AUTOSAR XML (schema 4-0-3)
package /ComponentTypes
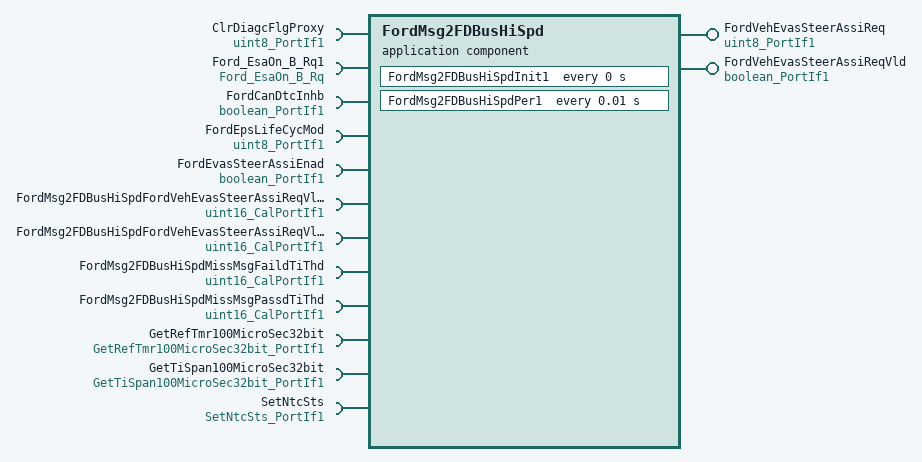
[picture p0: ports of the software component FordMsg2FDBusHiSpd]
  application sw component type FordMsg2FDBusHiSpd
    provide port FordVehEvasSteerAssiReq: nonqueued-sender-com-spec{data-element=Val, init-value=1}, provided-interface=uint8_PortIf1
    provide port FordVehEvasSteerAssiReqVld: nonqueued-sender-com-spec{data-element=Logl, init-value=0}, provided-interface=boolean_PortIf1
    12 x require port:
      ClrDiagcFlgProxy: nonqueued-receiver-com-spec{data-element=Val, filter=data-filter-type=ALWAYS, init-value=0}, required-interface=uint8_PortIf1
      Ford_EsaOn_B_Rq1: nonqueued-receiver-com-spec{data-element=Ford_EsaOn_B_Rq, filter=data-filter-type=ALWAYS, init-value=1}, required-interface=Ford_EsaOn_B_Rq
      FordCanDtcInhb: nonqueued-receiver-com-spec{data-element=Logl, filter=data-filter-type=ALWAYS, init-value=1}, required-interface=boolean_PortIf1
      FordEpsLifeCycMod: nonqueued-receiver-com-spec{data-element=Val, filter=data-filter-type=ALWAYS, init-value=0}, required-interface=uint8_PortIf1
      FordEvasSteerAssiEnad: nonqueued-receiver-com-spec{data-element=Logl, filter=data-filter-type=ALWAYS, init-value=0}, required-interface=boolean_PortIf1
      FordMsg2FDBusHiSpdFordVehEvasSteerAssiReqVldNotRxdTiThd: parameter-require-com-spec{init-value=5000, parameter=Val}, required-interface=uint16_CalPortIf1
      FordMsg2FDBusHiSpdFordVehEvasSteerAssiReqVldRxdTiThd: parameter-require-com-spec{init-value=5000, parameter=Val}, required-interface=uint16_CalPortIf1
      FordMsg2FDBusHiSpdMissMsgFaildTiThd: parameter-require-com-spec{init-value=5000, parameter=Val}, required-interface=uint16_CalPortIf1
      FordMsg2FDBusHiSpdMissMsgPassdTiThd: parameter-require-com-spec{init-value=0, parameter=Val}, required-interface=uint16_CalPortIf1
      GetRefTmr100MicroSec32bit: client-com-spec=Oper, required-interface=GetRefTmr100MicroSec32bit_PortIf1
      GetTiSpan100MicroSec32bit: client-com-spec=Oper, required-interface=GetTiSpan100MicroSec32bit_PortIf1
      SetNtcSts: client-com-spec=Oper, required-interface=SetNtcSts_PortIf1
    behavior FordMsg2FDBusHiSpd_InternalBehavior
      ar-typed-per-instance-memorys:
        9 x data, all with sw-calibration-access=READ-ONLY:
          ClrDiagcFlgProxyPrev: type=uint8
          FirstTranVldFlg: type=boolean
          FordVehEvasSteerAssiReqPrev: type=uint8
          FordVehEvasSteerAssiReqVldPrev: type=boolean
          FordVehMsg2FDMiss: type=boolean
          FordVehMsg2FDMissTmr: type=uint32
          FordVehMsg2FDNotRxdRefTi: type=uint32
          FordVehMsg2FDRxdRefTi: type=uint32
          FordVehMsg2FDRxdTmr: type=uint32
      timing event FordMsg2FDBusHiSpd_InitEvent: start-on-event=FordMsg2FDBusHiSpdInit1, period=0
      timing event TMT_FordMsg2FDBusHiSpdPer1: start-on-event=FordMsg2FDBusHiSpdPer1, period=0.01
      port-api-options:
        enable-take-address=false, indirect-api=false, port=ClrDiagcFlgProxy
        enable-take-address=false, indirect-api=false, port=Ford_EsaOn_B_Rq1
        enable-take-address=false, indirect-api=false, port=FordCanDtcInhb
        enable-take-address=false, indirect-api=false, port=FordEpsLifeCycMod
        enable-take-address=false, indirect-api=false, port=FordEvasSteerAssiEnad
        enable-take-address=false, indirect-api=false, port=FordMsg2FDBusHiSpdFordVehEvasSteerAssiReqVldNotRxdTiThd
        enable-take-address=false, indirect-api=false, port=FordMsg2FDBusHiSpdFordVehEvasSteerAssiReqVldRxdTiThd
        enable-take-address=false, indirect-api=false, port=FordMsg2FDBusHiSpdMissMsgFaildTiThd
        enable-take-address=false, indirect-api=false, port=FordVehEvasSteerAssiReq
        enable-take-address=false, indirect-api=false, port=FordVehEvasSteerAssiReqVld
        enable-take-address=false, indirect-api=false, port=GetRefTmr100MicroSec32bit
        enable-take-address=false, indirect-api=false, port=GetTiSpan100MicroSec32bit
        enable-take-address=false, indirect-api=false, port=SetNtcSts
      runnable FordMsg2FDBusHiSpdInit1
        sync call SC_GetRefTmr100MicroSec32bit_Oper: operation=GetRefTmr100MicroSec32bit.Oper, timeout=0
      runnable FordMsg2FDBusHiSpdPer1
        data-receive-point-by-arguments:
          5 x access:
            REC_ClrDiagcFlgProxy_Val: accessed-variable=ClrDiagcFlgProxy.Val
            REC_Ford_EsaOn_B_Rq1_Ford_EsaOn_B_Rq: accessed-variable=Ford_EsaOn_B_Rq1.Ford_EsaOn_B_Rq
            REC_FordCanDtcInhb_Logl: accessed-variable=FordCanDtcInhb.Logl
            REC_FordEpsLifeCycMod_Val: accessed-variable=FordEpsLifeCycMod.Val
            REC_FordEvasSteerAssiEnad_Logl: accessed-variable=FordEvasSteerAssiEnad.Logl
        data-send-points:
          access SEND_FordVehEvasSteerAssiReq_Val: accessed-variable=FordVehEvasSteerAssiReq.Val
          access SEND_FordVehEvasSteerAssiReqVld_Logl: accessed-variable=FordVehEvasSteerAssiReqVld.Logl
        sync call SC_GetRefTmr100MicroSec32bit_Oper: operation=GetRefTmr100MicroSec32bit.Oper, timeout=0
        sync call SC_GetTiSpan100MicroSec32bit_Oper: operation=GetTiSpan100MicroSec32bit.Oper, timeout=0
        sync call SC_SetNtcSts_Oper: operation=SetNtcSts.Oper, timeout=0
  swc implementation FordMsg2FDBusHiSpd_Implementation: behavior=FordMsg2FDBusHiSpd_InternalBehavior
    code-descriptors:
      code Default: artifact-descriptors=autosar-engineering-object={short-label=Default, category=SWSRC}
